VERSION ""

NS_ :

BS_:

BU_:

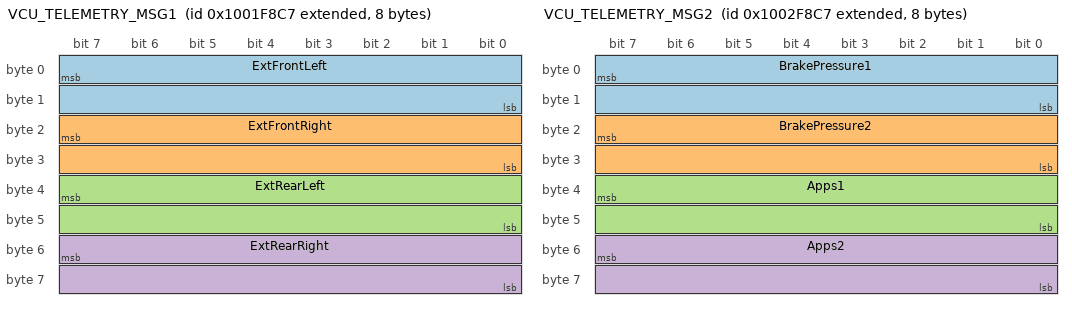
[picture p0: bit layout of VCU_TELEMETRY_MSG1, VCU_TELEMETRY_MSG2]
BO_ 2416048327 VCU_TELEMETRY_MSG1: 8 Vector__XXX
 SG_ ExtFrontLeft : 7|16@0- (0.1,0.0) [0|0] "mm" Vector__XXX
 SG_ ExtFrontRight : 23|16@0- (0.1,0.0) [0|0] "mm" Vector__XXX
 SG_ ExtRearLeft : 39|16@0- (0.1,0.0) [0|0] "mm" Vector__XXX
 SG_ ExtRearRight : 55|16@0- (0.1,0.0) [0|0] "mm" Vector__XXX

BO_ 2416113863 VCU_TELEMETRY_MSG2: 8 Vector__XXX
 SG_ BrakePressure1 : 7|16@0+ (0.1,0.0) [0|0] "bar" Vector__XXX
 SG_ BrakePressure2 : 23|16@0+ (0.1,0.0) [0|0] "bar" Vector__XXX
 SG_ Apps1 : 39|16@0+ (0.1,0.0) [0|0] "%" Vector__XXX
 SG_ Apps2 : 55|16@0+ (0.1,0.0) [0|0] "%" Vector__XXX

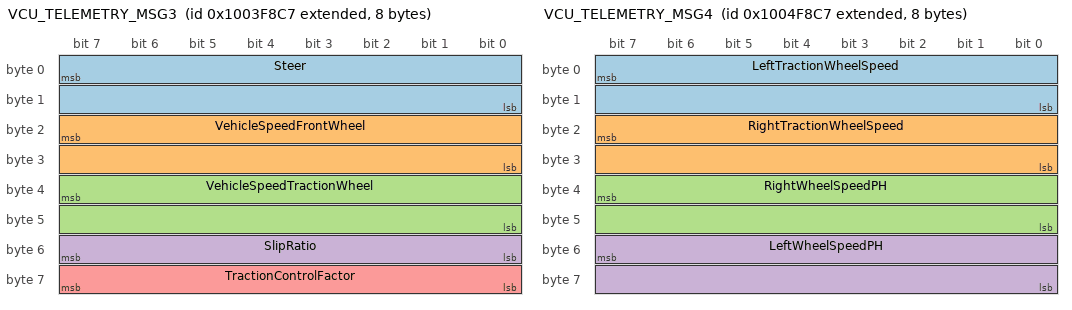
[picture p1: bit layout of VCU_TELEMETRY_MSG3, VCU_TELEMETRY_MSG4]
BO_ 2416179399 VCU_TELEMETRY_MSG3: 8 Vector__XXX
 SG_ Steer : 7|16@0- (0.01,0.0) [0|0] "deg" Vector__XXX
 SG_ VehicleSpeedFrontWheel : 23|16@0+ (0.1,0.0) [0|0] "km/h" Vector__XXX
 SG_ VehicleSpeedTractionWheel : 39|16@0+ (0.1,0.0) [0|0] "km/h" Vector__XXX
 SG_ SlipRatio : 55|8@0+ (0.01,0.0) [0|0] "" Vector__XXX
 SG_ TractionControlFactor : 63|8@0+ (0.01,0.0) [0|0] "" Vector__XXX

BO_ 2416244935 VCU_TELEMETRY_MSG4: 8 Vector__XXX
 SG_ LeftTractionWheelSpeed : 7|16@0+ (0.1,0.0) [0|0] "km/h" Vector__XXX
 SG_ RightTractionWheelSpeed : 23|16@0+ (0.1,0.0) [0|0] "km/h" Vector__XXX
 SG_ RightWheelSpeedPH : 39|16@0+ (0.1,0.0) [0|0] "km/h" Vector__XXX
 SG_ LeftWheelSpeedPH : 55|16@0+ (0.1,0.0) [0|0] "km/h" Vector__XXX

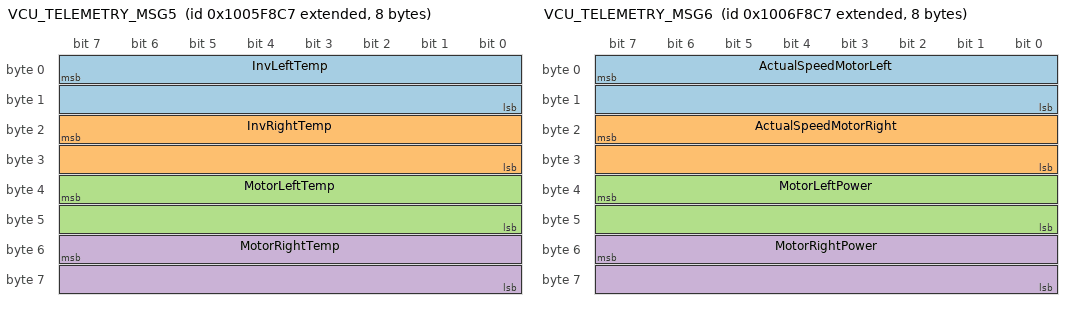
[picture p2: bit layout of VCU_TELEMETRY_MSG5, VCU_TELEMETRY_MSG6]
BO_ 2416310471 VCU_TELEMETRY_MSG5: 8 Vector__XXX
 SG_ InvLeftTemp : 7|16@0+ (0.1,0.0) [0|0] "°C" Vector__XXX
 SG_ InvRightTemp : 23|16@0+ (0.1,0.0) [0|0] "°C" Vector__XXX
 SG_ MotorLeftTemp : 39|16@0+ (0.1,0.0) [0|0] "°C" Vector__XXX
 SG_ MotorRightTemp : 55|16@0+ (0.1,0.0) [0|0] "°C" Vector__XXX

BO_ 2416376007 VCU_TELEMETRY_MSG6: 8 Vector__XXX
 SG_ ActualSpeedMotorLeft : 7|16@0- (1,0) [0|0] "rpm" Vector__XXX
 SG_ ActualSpeedMotorRight : 23|16@0- (1,0) [0|0] "rpm" Vector__XXX
 SG_ MotorLeftPower : 39|16@0- (0.1,0.0) [0|0] "kW" Vector__XXX
 SG_ MotorRightPower : 55|16@0- (0.1,0.0) [0|0] "kW" Vector__XXX

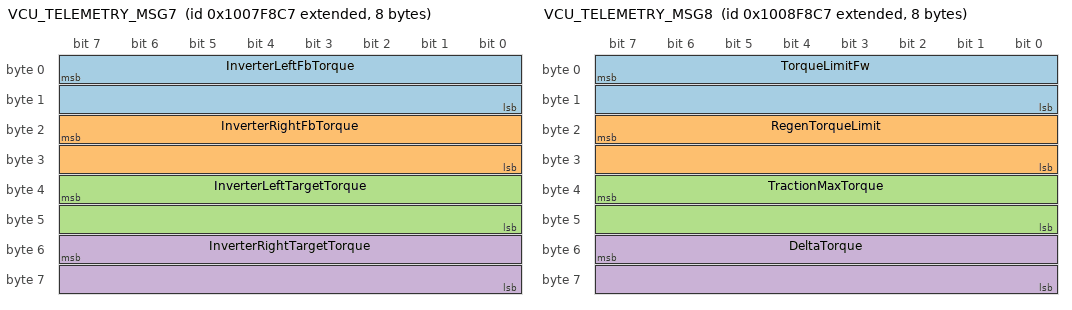
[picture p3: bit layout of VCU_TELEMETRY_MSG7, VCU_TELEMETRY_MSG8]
BO_ 2416441543 VCU_TELEMETRY_MSG7: 8 Vector__XXX
 SG_ InverterLeftFbTorque : 7|16@0- (0.1,0.0) [0|0] "Nm" Vector__XXX
 SG_ InverterRightFbTorque : 23|16@0- (0.1,0.0) [0|0] "Nm" Vector__XXX
 SG_ InverterLeftTargetTorque : 39|16@0- (0.1,0.0) [0|0] "Nm" Vector__XXX
 SG_ InverterRightTargetTorque : 55|16@0- (0.1,0.0) [0|0] "Nm" Vector__XXX

BO_ 2416507079 VCU_TELEMETRY_MSG8: 8 Vector__XXX
 SG_ TorqueLimitFw : 7|16@0+ (0.1,0.0) [0|0] "Nm" Vector__XXX
 SG_ RegenTorqueLimit : 23|16@0+ (0.1,0.0) [0|0] "Nm" Vector__XXX
 SG_ TractionMaxTorque : 39|16@0+ (0.1,0.0) [0|0] "Nm" Vector__XXX
 SG_ DeltaTorque : 55|16@0+ (0.1,0.0) [0|0] "Nm" Vector__XXX

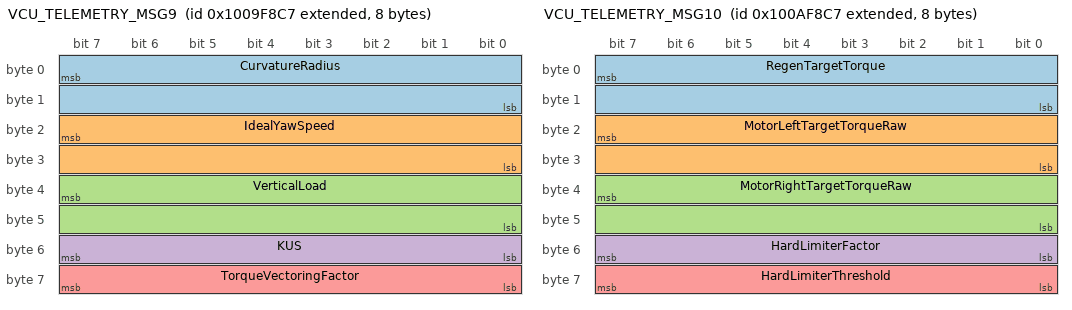
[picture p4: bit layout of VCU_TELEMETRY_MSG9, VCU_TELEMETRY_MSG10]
BO_ 2416572615 VCU_TELEMETRY_MSG9: 8 Vector__XXX
 SG_ CurvatureRadius : 7|16@0+ (0.1,0.0) [0|0] "m" Vector__XXX
 SG_ IdealYawSpeed : 23|16@0+ (0.1,0.0) [0|0] "°/s" Vector__XXX
 SG_ VerticalLoad : 39|16@0- (0.1,0.0) [0|0] "N" Vector__XXX
 SG_ KUS : 55|8@0- (0.1,0.0) [0|0] "" Vector__XXX
 SG_ TorqueVectoringFactor : 63|8@0- (0.01,0.0) [0|0] "" Vector__XXX

BO_ 2416638151 VCU_TELEMETRY_MSG10: 8 Vector__XXX
 SG_ RegenTargetTorque : 7|16@0+ (0.1,0.0) [0|0] "Nm" Vector__XXX
 SG_ MotorLeftTargetTorqueRaw : 23|16@0+ (0.1,0.0) [0|0] "Nm" Vector__XXX
 SG_ MotorRightTargetTorqueRaw : 39|16@0+ (0.1,0.0) [0|0] "Nm" Vector__XXX
 SG_ HardLimiterFactor : 55|8@0+ (0.01,0.0) [0|0] "" Vector__XXX
 SG_ HardLimiterThreshold : 63|8@0+ (0.01,0.0) [0|0] "" Vector__XXX

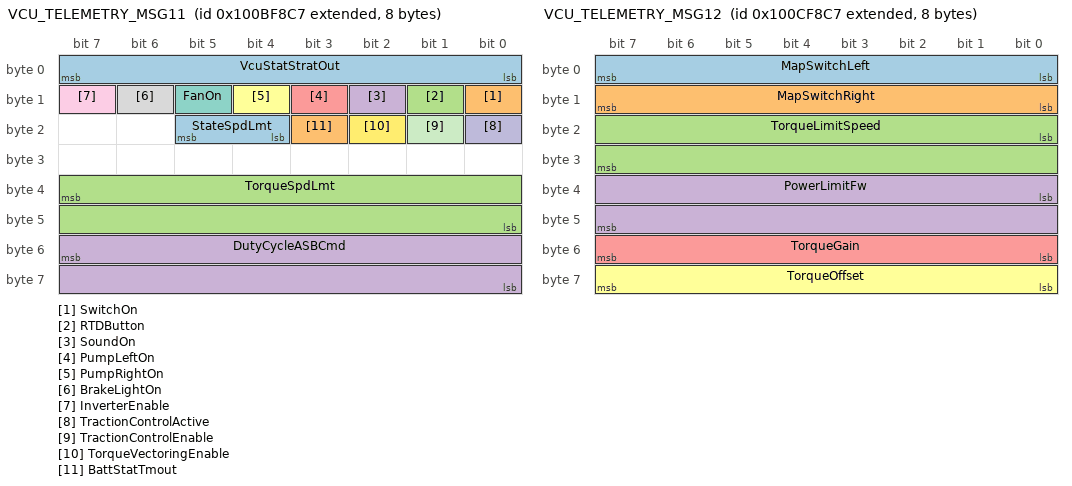
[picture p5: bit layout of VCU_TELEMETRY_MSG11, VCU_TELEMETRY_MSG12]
BO_ 2416703687 VCU_TELEMETRY_MSG11: 8 Vector__XXX
 SG_ VcuStatStratOut : 0|8@1+ (1.0,0.0) [0|0] "-" Vector__XXX
 SG_ SwitchOn : 8|1@1+ (1,0) [0|0] "" Vector__XXX
 SG_ RTDButton : 9|1@1+ (1,0) [0|0] "" Vector__XXX
 SG_ SoundOn : 10|1@1+ (1,0) [0|0] "" Vector__XXX
 SG_ PumpLeftOn : 11|1@1+ (1,0) [0|0] "" Vector__XXX
 SG_ PumpRightOn : 12|1@1+ (1,0) [0|0] "" Vector__XXX
 SG_ FanOn : 13|1@1+ (1,0) [0|0] "" Vector__XXX
 SG_ BrakeLightOn : 14|1@1+ (1,0) [0|0] "" Vector__XXX
 SG_ InverterEnable : 15|1@1+ (1,0) [0|0] "" Vector__XXX
 SG_ TractionControlActive : 16|1@1+ (1,0) [0|0] "" Vector__XXX
 SG_ TractionControlEnable : 17|1@1+ (1,0) [0|0] "" Vector__XXX
 SG_ TorqueVectoringEnable : 18|1@1+ (1,0) [0|0] "" Vector__XXX
 SG_ StateSpdLmt : 21|2@0+ (1.0,0.0) [0|0] "-" Vector__XXX
 SG_ BattStatTmout : 19|1@1+ (1,0) [0|0] "" Vector__XXX
 SG_ TorqueSpdLmt : 39|16@0+ (0.01,0.0) [0|0] "Nm" Vector__XXX
 SG_ DutyCycleASBCmd : 55|16@0+ (1,0) [0|0] "" Vector__XXX

BO_ 2416769223 VCU_TELEMETRY_MSG12: 8 Vector__XXX
 SG_ MapSwitchLeft : 0|8@1+ (1,0) [0|0] "" Vector__XXX
 SG_ MapSwitchRight : 8|8@1+ (1,0) [0|0] "" Vector__XXX
 SG_ TorqueLimitSpeed : 16|16@1+ (0.1,0.0) [0|0] "" Vector__XXX
 SG_ PowerLimitFw : 32|16@1+ (0.1,0.0) [0|0] "" Vector__XXX
 SG_ TorqueGain : 48|8@1+ (0.01,0.0) [0|0] "" Vector__XXX
 SG_ TorqueOffset : 56|8@1- (1,0) [0|0] "" Vector__XXX

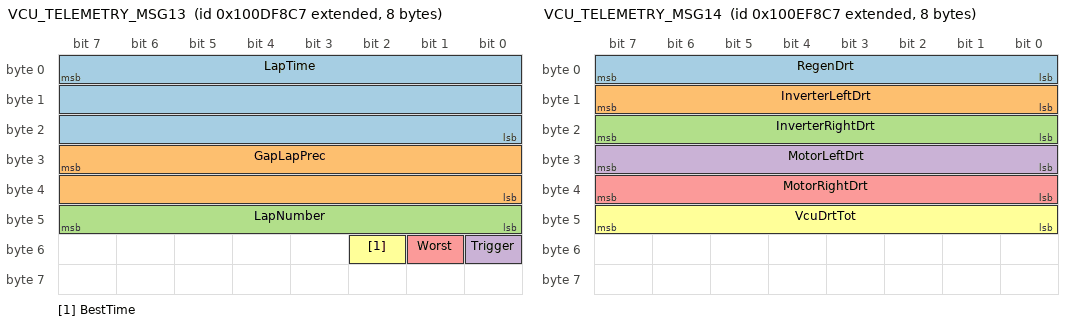
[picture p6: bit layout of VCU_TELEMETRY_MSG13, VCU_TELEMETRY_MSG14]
BO_ 2416834759 VCU_TELEMETRY_MSG13: 8 Vector__XXX
 SG_ LapTime : 7|24@0+ (1,0) [0|0] "" Vector__XXX
 SG_ GapLapPrec : 31|16@0+ (1,0) [0|0] "" Vector__XXX
 SG_ LapNumber : 40|8@1+ (1,0) [0|0] "" Vector__XXX
 SG_ Trigger : 48|1@1+ (1,0) [0|0] "" Vector__XXX
 SG_ Worst : 49|1@1+ (1,0) [0|0] "" Vector__XXX
 SG_ BestTime : 50|1@1+ (1,0) [0|0] "" Vector__XXX

BO_ 2416900295 VCU_TELEMETRY_MSG14: 8 Vector__XXX
 SG_ RegenDrt : 7|8@0+ (1,0) [0|0] "%" Vector__XXX
 SG_ InverterLeftDrt : 15|8@0+ (1,0) [0|0] "%" Vector__XXX
 SG_ InverterRightDrt : 23|8@0+ (1,0) [0|0] "%" Vector__XXX
 SG_ MotorLeftDrt : 31|8@0+ (1,0) [0|0] "%" Vector__XXX
 SG_ MotorRightDrt : 39|8@0+ (1,0) [0|0] "%" Vector__XXX
 SG_ VcuDrtTot : 47|8@0+ (1,0) [0|0] "%" Vector__XXX

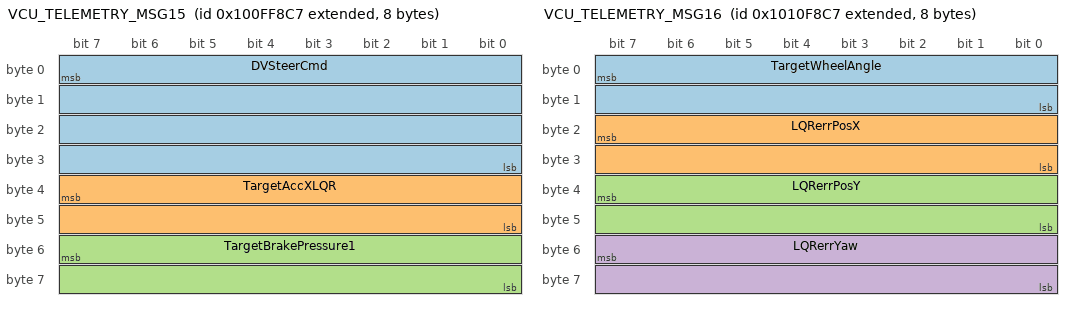
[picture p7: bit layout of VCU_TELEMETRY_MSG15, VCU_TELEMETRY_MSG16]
BO_ 2416965831 VCU_TELEMETRY_MSG15: 8 Vector__XXX
 SG_ DVSteerCmd : 7|32@0- (1,0) [0|0] "inch" Vector__XXX
 SG_ TargetAccXLQR : 39|16@0- (0.01,0.0) [0|0] "m/s2" Vector__XXX
 SG_ TargetBrakePressure1 : 55|16@0+ (0.1,0.0) [0|0] "bar" Vector__XXX

BO_ 2417031367 VCU_TELEMETRY_MSG16: 8 Vector__XXX
 SG_ TargetWheelAngle : 7|16@0- (0.01,0.0) [0|0] "deg" Vector__XXX
 SG_ LQRerrPosX : 23|16@0- (0.01,0.0) [0|0] "m" Vector__XXX
 SG_ LQRerrPosY : 39|16@0- (0.01,0.0) [0|0] "m" Vector__XXX
 SG_ LQRerrYaw : 55|16@0- (0.01,0.0) [0|0] "deg" Vector__XXX

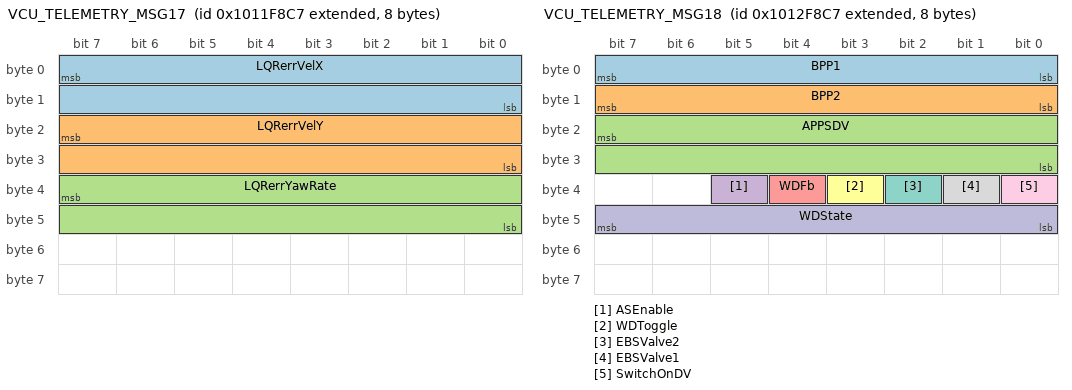
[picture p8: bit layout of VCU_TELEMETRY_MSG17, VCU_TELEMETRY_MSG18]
BO_ 2417096903 VCU_TELEMETRY_MSG17: 8 Vector__XXX
 SG_ LQRerrVelX : 7|16@0- (0.01,0.0) [0|0] "m/s" Vector__XXX
 SG_ LQRerrVelY : 23|16@0- (0.01,0.0) [0|0] "m/s" Vector__XXX
 SG_ LQRerrYawRate : 39|16@0- (0.01,0.0) [0|0] "deg/s" Vector__XXX

BO_ 2417162439 VCU_TELEMETRY_MSG18: 8 Vector__XXX
 SG_ BPP1 : 7|8@0+ (0.1,0.0) [0|0] "bar" Vector__XXX
 SG_ BPP2 : 15|8@0+ (0.1,0.0) [0|0] "bar" Vector__XXX
 SG_ APPSDV : 23|16@0+ (0.1,0.0) [0|0] "%" Vector__XXX
 SG_ ASEnable : 37|1@0+ (1,0) [0|0] "" Vector__XXX
 SG_ WDFb : 36|1@0+ (1,0) [0|0] "" Vector__XXX
 SG_ WDToggle : 35|1@0+ (1,0) [0|0] "" Vector__XXX
 SG_ EBSValve2 : 34|1@0+ (1,0) [0|0] "" Vector__XXX
 SG_ EBSValve1 : 33|1@0+ (1,0) [0|0] "" Vector__XXX
 SG_ SwitchOnDV : 32|1@0+ (1,0) [0|0] "" Vector__XXX
 SG_ WDState : 47|8@0+ (1.0,0.0) [0|0] "-" Vector__XXX

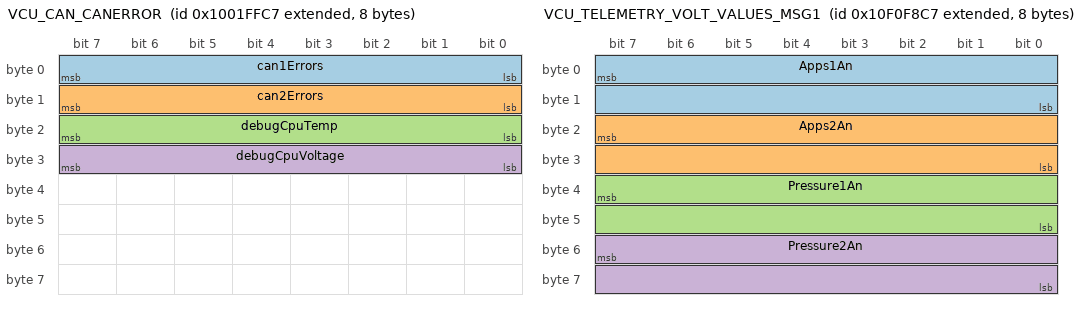
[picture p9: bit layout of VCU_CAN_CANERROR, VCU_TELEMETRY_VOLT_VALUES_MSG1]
BO_ 2416050119 VCU_CAN_CANERROR: 8 Vector__XXX
 SG_ can1Errors : 0|8@1+ (1,0) [0|0] "" Vector__XXX
 SG_ can2Errors : 8|8@1+ (1,0) [0|0] "" Vector__XXX
 SG_ debugCpuTemp : 16|8@1- (1,0) [0|0] "" Vector__XXX
 SG_ debugCpuVoltage : 24|8@1- (1,0) [0|0] "" Vector__XXX

BO_ 2431711431 VCU_TELEMETRY_VOLT_VALUES_MSG1: 8 Vector__XXX
 SG_ Apps1An : 7|16@0+ (0.01,0.0) [0|0] "" Vector__XXX
 SG_ Apps2An : 23|16@0+ (0.01,0.0) [0|0] "" Vector__XXX
 SG_ Pressure1An : 39|16@0+ (0.01,0.0) [0|0] "" Vector__XXX
 SG_ Pressure2An : 55|16@0+ (0.01,0.0) [0|0] "" Vector__XXX

BO_ 2431776967 VCU_TELEMETRY_VOLT_VALUES_MSG2: 8 Vector__XXX
 SG_ SteerAn : 7|16@0+ (0.01,0.0) [0|0] "" Vector__XXX

BO_ 2416179417 TELEMETRY_VCU_MSG3: 8 Vector__XXX
 SG_ ASMS : 7|16@0+ (0.01,0.0) [0|0] "V" Vector__XXX

CM_ BO_ 2416048327 "MessageComment";
CM_ SG_ 2416048327 ExtRearRight "Comment";
CM_ SG_ 2416048327 ExtRearLeft "Comment";
CM_ SG_ 2416048327 ExtFrontRight "Comment";
CM_ SG_ 2416048327 ExtFrontLeft "Comment";
CM_ BO_ 2416113863 "MessageComment";
CM_ SG_ 2416113863 Apps2 "Comment";
CM_ SG_ 2416113863 Apps1 "Comment";
CM_ SG_ 2416113863 BrakePressure2 "Comment";
CM_ SG_ 2416113863 BrakePressure1 "Comment";
CM_ BO_ 2416179399 "MessageComment";
CM_ SG_ 2416179399 TractionControlFactor "Comment";
CM_ SG_ 2416179399 SlipRatio "Comment";
CM_ SG_ 2416179399 VehicleSpeedTractionWheel "Comment";
CM_ SG_ 2416179399 VehicleSpeedFrontWheel "Comment";
CM_ SG_ 2416179399 Steer "Comment";
CM_ BO_ 2416244935 "MessageComment";
CM_ SG_ 2416244935 LeftWheelSpeedPH "Comment";
CM_ SG_ 2416244935 RightWheelSpeedPH "Comment";
CM_ SG_ 2416244935 RightTractionWheelSpeed "Comment";
CM_ SG_ 2416244935 LeftTractionWheelSpeed "Comment";
CM_ BO_ 2416310471 "MessageComment";
CM_ SG_ 2416310471 MotorRightTemp "Comment";
CM_ SG_ 2416310471 MotorLeftTemp "Comment";
CM_ SG_ 2416310471 InvRightTemp "Comment";
CM_ SG_ 2416310471 InvLeftTemp "Comment";
CM_ BO_ 2416376007 "MessageComment";
CM_ SG_ 2416376007 MotorRightPower "Comment";
CM_ SG_ 2416376007 MotorLeftPower "Comment";
CM_ SG_ 2416376007 ActualSpeedMotorRight "Comment";
CM_ SG_ 2416376007 ActualSpeedMotorLeft "Comment";
CM_ BO_ 2416441543 "MessageComment";
CM_ SG_ 2416441543 InverterRightTargetTorque "Comment";
CM_ SG_ 2416441543 InverterLeftTargetTorque "Comment";
CM_ SG_ 2416441543 InverterRightFbTorque "Comment";
CM_ SG_ 2416441543 InverterLeftFbTorque "Comment";
CM_ BO_ 2416507079 "MessageComment";
CM_ SG_ 2416507079 DeltaTorque "Comment";
CM_ SG_ 2416507079 TractionMaxTorque "Comment";
CM_ SG_ 2416507079 RegenTorqueLimit "Comment";
CM_ SG_ 2416507079 TorqueLimitFw "Comment";
CM_ BO_ 2416572615 "MessageComment";
CM_ SG_ 2416572615 TorqueVectoringFactor "Comment";
CM_ SG_ 2416572615 KUS "Comment";
CM_ SG_ 2416572615 VerticalLoad "Comment";
CM_ SG_ 2416572615 IdealYawSpeed "Comment";
CM_ SG_ 2416572615 CurvatureRadius "Comment";
CM_ BO_ 2416638151 "MessageComment";
CM_ SG_ 2416638151 HardLimiterThreshold "Comment";
CM_ SG_ 2416638151 HardLimiterFactor "Comment";
CM_ SG_ 2416638151 MotorRightTargetTorqueRaw "Comment";
CM_ SG_ 2416638151 MotorLeftTargetTorqueRaw "Comment";
CM_ SG_ 2416638151 RegenTargetTorque "Comment";
CM_ BO_ 2416703687 "MessageComment";
CM_ SG_ 2416703687 DutyCycleASBCmd "Comment";
CM_ SG_ 2416703687 TorqueSpdLmt "Comment";
CM_ SG_ 2416703687 BattStatTmout "Comment";
CM_ SG_ 2416703687 StateSpdLmt "Comment";
CM_ SG_ 2416703687 TorqueVectoringEnable "Comment";
CM_ SG_ 2416703687 TractionControlEnable "Comment";
CM_ SG_ 2416703687 TractionControlActive "Comment";
CM_ SG_ 2416703687 InverterEnable "Comment";
CM_ SG_ 2416703687 BrakeLightOn "Comment";
CM_ SG_ 2416703687 FanOn "Comment";
CM_ SG_ 2416703687 PumpRightOn "Comment";
CM_ SG_ 2416703687 PumpLeftOn "Comment";
CM_ SG_ 2416703687 SoundOn "Comment";
CM_ SG_ 2416703687 RTDButton "Comment";
CM_ SG_ 2416703687 SwitchOn "Comment";
CM_ SG_ 2416703687 VcuStatStratOut "VcuStrategyState";
CM_ BO_ 2416769223 "MessageComment";
CM_ SG_ 2416769223 TorqueOffset "Comment";
CM_ SG_ 2416769223 TorqueGain "Comment";
CM_ SG_ 2416769223 PowerLimitFw "Comment";
CM_ SG_ 2416769223 TorqueLimitSpeed "Comment";
CM_ SG_ 2416769223 MapSwitchRight "Comment";
CM_ SG_ 2416769223 MapSwitchLeft "Comment";
CM_ BO_ 2416834759 "MessageComment";
CM_ SG_ 2416834759 BestTime "Comment";
CM_ SG_ 2416834759 Worst "Comment";
CM_ SG_ 2416834759 Trigger "Comment";
CM_ SG_ 2416834759 LapNumber "Comment";
CM_ SG_ 2416834759 GapLapPrec "Comment";
CM_ SG_ 2416834759 LapTime "Comment";
CM_ BO_ 2416900295 "nan";
CM_ SG_ 2416900295 VcuDrtTot "Comment";
CM_ SG_ 2416900295 MotorRightDrt "Comment";
CM_ SG_ 2416900295 MotorLeftDrt "Comment";
CM_ SG_ 2416900295 InverterRightDrt "Comment";
CM_ SG_ 2416900295 InverterLeftDrt "Comment";
CM_ SG_ 2416900295 RegenDrt "Comment";
CM_ BO_ 2416965831 "nan";
CM_ SG_ 2416965831 TargetBrakePressure1 "SignalComment";
CM_ SG_ 2416965831 TargetAccXLQR "SignalComment";
CM_ SG_ 2416965831 DVSteerCmd "SignalComment";
CM_ BO_ 2417031367 "nan";
CM_ SG_ 2417031367 LQRerrYaw "SignalComment";
CM_ SG_ 2417031367 LQRerrPosY "SignalComment";
CM_ SG_ 2417031367 LQRerrPosX "SignalComment";
CM_ SG_ 2417031367 TargetWheelAngle "SignalComment";
CM_ BO_ 2417096903 "nan";
CM_ SG_ 2417096903 LQRerrYawRate "SignalComment";
CM_ SG_ 2417096903 LQRerrVelY "SignalComment";
CM_ SG_ 2417096903 LQRerrVelX "SignalComment";
CM_ BO_ 2417162439 "nan";
CM_ SG_ 2417162439 WDState "SignalComment";
CM_ SG_ 2417162439 SwitchOnDV "SignalComment";
CM_ SG_ 2417162439 EBSValve1 "SignalComment";
CM_ SG_ 2417162439 EBSValve2 "SignalComment";
CM_ SG_ 2417162439 WDToggle "SignalComment";
CM_ SG_ 2417162439 WDFb "SignalComment";
CM_ SG_ 2417162439 ASEnable "SignalComment";
CM_ SG_ 2417162439 APPSDV "SignalComment";
CM_ SG_ 2417162439 BPP2 "SignalComment";
CM_ SG_ 2417162439 BPP1 "SignalComment";
CM_ BO_ 2416050119 "nan";
CM_ SG_ 2416050119 debugCpuVoltage "SignalComment";
CM_ SG_ 2416050119 debugCpuTemp "SignalComment";
CM_ SG_ 2416050119 can2Errors "SignalComment";
CM_ SG_ 2416050119 can1Errors "SignalComment";
CM_ BO_ 2431711431 "nan";
CM_ SG_ 2431711431 Pressure2An "SignalComment";
CM_ SG_ 2431711431 Pressure1An "SignalComment";
CM_ SG_ 2431711431 Apps2An "SignalComment";
CM_ SG_ 2431711431 Apps1An "SignalComment";
CM_ BO_ 2431776967 "nan";
CM_ SG_ 2431776967 SteerAn "SignalComment";
CM_ BO_ 2416179417 "nan";
CM_ SG_ 2416179417 ASMS "SignalComment";

VAL_ 2416703687 StateSpdLmt 1 "pilotDriving" 2 "Supervisor" 3 "Controller" ;
VAL_ 2416703687 VcuStatStratOut 0 "StrategyStateHardStop" 1 "StrategyStateIdle" 2 "StrategyStateWaitSwitch" 3 "StrategyStateDischarge" 4 "StrategyStateNoTraction" 5 "StrategyStatePrecharge" 6 "StrategyStateWait" 7 "StrategyStateBspdSw" 8 "StrategyStateNormalMode" 9 "StrategyStateLaunchMode" ;
VAL_ 2417162439 WDState 0 "WDStateIdle" 1 "WDStateTest1" 2 "WDStateTest2" 3 "WDStateCheckSDC" 4 "WDStateCheckRes" 5 "WDStateCheckPressurePneumatic" 6 "WDStateDelay" 7 "WDStateCheckPressureOil" 8 "WDStateStopMonitoring" 9 "WDStateEmergency" ;
